VERSION "SignalScope beginner example"

NS_ :

BS_:

BU_: Sensor Dashboard

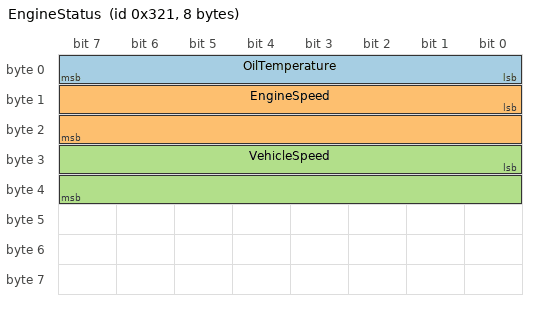
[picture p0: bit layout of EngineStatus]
BO_ 801 EngineStatus: 8 Sensor
 SG_ OilTemperature : 0|8@1+ (1,-40) [-40|215] "degC" Dashboard
 SG_ EngineSpeed : 8|16@1+ (0.25,0) [0|16383.75] "rpm" Dashboard
 SG_ VehicleSpeed : 24|16@1+ (0.01,0) [0|655.35] "km/h" Dashboard

CM_ BO_ 801 "Synthetic learning frame. Replace this DBC with one that matches your network.";
CM_ SG_ 801 OilTemperature "Raw byte 40 represents 0 degC; raw byte 130 represents 90 degC.";
